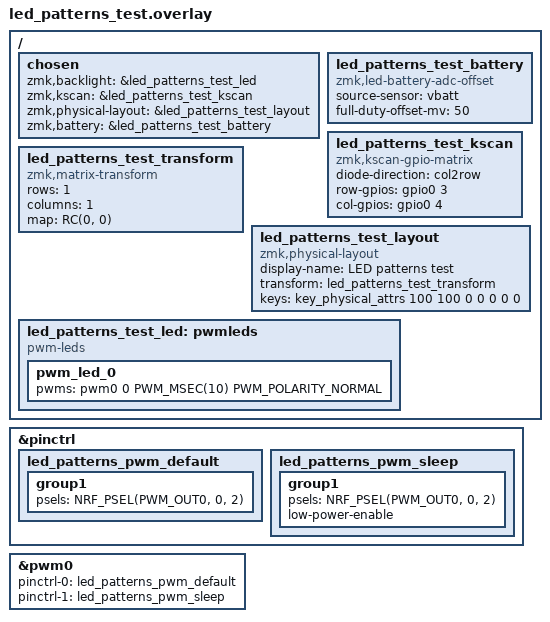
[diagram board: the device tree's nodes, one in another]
/*
 * Copyright (c) 2026 amgskobo
 * SPDX-License-Identifier: MIT
 */

#include <zephyr/dt-bindings/pwm/pwm.h>
#include <zephyr/dt-bindings/gpio/gpio.h>
#include <physical_layouts.dtsi>
#include <dt-bindings/zmk/matrix_transform.h>

&pinctrl {
    led_patterns_pwm_default: led_patterns_pwm_default {
        group1 {
            psels = <NRF_PSEL(PWM_OUT0, 0, 2)>;
        };
    };

    led_patterns_pwm_sleep: led_patterns_pwm_sleep {
        group1 {
            psels = <NRF_PSEL(PWM_OUT0, 0, 2)>;
            low-power-enable;
        };
    };
};

&pwm0 {
    status = "okay";
    pinctrl-0 = <&led_patterns_pwm_default>;
    pinctrl-1 = <&led_patterns_pwm_sleep>;
    pinctrl-names = "default", "sleep";
};

/ {
    chosen {
        zmk,backlight = &led_patterns_test_led;
        zmk,kscan = &led_patterns_test_kscan;
        zmk,physical-layout = &led_patterns_test_layout;
        zmk,battery = &led_patterns_test_battery;
    };

    led_patterns_test_battery: led_patterns_test_battery {
        compatible = "zmk,led-battery-adc-offset";
        source-sensor = <&vbatt>;
        full-duty-offset-mv = <50>;
    };

    led_patterns_test_kscan: led_patterns_test_kscan {
        compatible = "zmk,kscan-gpio-matrix";
        diode-direction = "col2row";
        row-gpios = <&gpio0 3 (GPIO_ACTIVE_HIGH | GPIO_PULL_DOWN)>;
        col-gpios = <&gpio0 4 GPIO_ACTIVE_HIGH>;
    };

    led_patterns_test_transform: led_patterns_test_transform {
        compatible = "zmk,matrix-transform";
        rows = <1>;
        columns = <1>;
        map = <RC(0, 0)>;
    };

    led_patterns_test_layout: led_patterns_test_layout {
        compatible = "zmk,physical-layout";
        display-name = "LED patterns test";
        transform = <&led_patterns_test_transform>;
        keys = <&key_physical_attrs 100 100 0 0 0 0 0>;
    };

    led_patterns_test_led: pwmleds {
        compatible = "pwm-leds";

        pwm_led_0 {
            pwms = <&pwm0 0 PWM_MSEC(10) PWM_POLARITY_NORMAL>;
        };
    };
};
